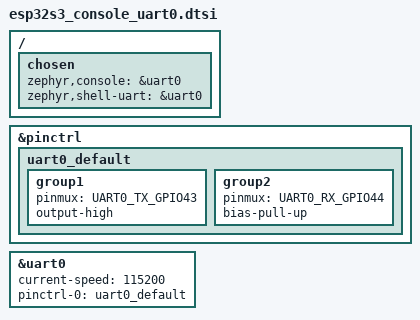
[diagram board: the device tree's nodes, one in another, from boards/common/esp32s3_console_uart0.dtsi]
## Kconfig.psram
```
# SPDX-License-Identifier: MIT
#
# DT-driven PSRAM auto-enable for ESP32 boards.
#
# Upstream Zephyr's esp32*_wroom_n*r*.dtsi files override psram0 size when
# the chip variant has PSRAM stuffed (R-suffix in the Espressif part number).
# We auto-enable PSRAM whenever the DTS size is non-zero — the upstream
# Kconfig.spiram then auto-reads ESP_SPIRAM_SIZE from the same DT property.
#
# Boards without PSRAM include a non-R-suffix dtsi (e.g. esp32s3_wroom_n8),
# which leaves psram0 at size = 0 — auto-detect leaves PSRAM off for them.
# ESP32-C3 and ESP32-C6 are outside Kconfig.spiram's SOC gate entirely, so
# this symbol doesn't exist on those builds — no effect.
#
# Mode (QUAD vs OCT) cannot be auto-picked here: upstream Kconfig.spiram
# sets an unconditional `default SPIRAM_MODE_QUAD` on the choice, which wins
# over any conditional default we'd add. ESP32-S3 R8 boards (8 MB OPI octal
# PSRAM) must set CONFIG_SPIRAM_MODE_OCT=y in their board.conf. R2 boards
# (2 MB QSPI quad) need nothing — QUAD is the upstream default.

config ESP_SPIRAM
	default y if (SOC_SERIES_ESP32 || SOC_SERIES_ESP32S2 || SOC_SERIES_ESP32S3 || SOC_SERIES_ESP32C5) && \
		"$(dt_node_int_prop_int,$(dt_nodelabel_path,psram0),size)" != 0
```

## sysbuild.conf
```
# ZephCore Sysbuild Configuration
# Enables the MCUboot bootloader whenever --sysbuild is passed. Used by the
# ESP32-S3/C-series release builds (companion and repeater: MCUboot @ 0x0, app
# @ 0x10000) and by any build with wifi_ota.conf. Classic ESP32, nRF52, nRF54L,
# MG24 and STM32WL builds do not use --sysbuild.

SB_CONFIG_BOOTLOADER_MCUBOOT=y
SB_CONFIG_MCUBOOT_MODE_OVERWRITE_ONLY=y

# Explicit since Zephyr 4.5: 51ef282b5f1 moved Espressif sysbuild to the generic
# MCUboot defaults, whose signature type is RSA.  That silently turned the
# bootloader into an RSA-2048 verifier keyed to MCUboot's public development
# key -- no real security, ~19 KB of mbedTLS/PSA that overflowed the 64 KB
# MCUboot slot on several boards (the app written at 0x10000 then overwrites
# the bootloader's tail), and a bootloader that rejects the hash-only images
# every deployed ESP32 node and WiFi-OTA update uses.  NONE = hash check only,
# exactly what v4.4 built.  Moving to real signing (own key) is a separate
# decision with OTA consequences.
SB_CONFIG_BOOT_SIGNATURE_TYPE_NONE=y
```

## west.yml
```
manifest:
  remotes:
    - name: zephyrproject-rtos
      url-base: https://github.com/zephyrproject-rtos

  projects:
    - name: zephyr
      remote: zephyrproject-rtos
      revision: 54b1e23b9ce303480ccbcab4b80d6f2f8442dac1
      import: true

  self:
    path: zephcore
```

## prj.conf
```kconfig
# ZephCore - Main Project Configuration
#
# This file contains ONLY console/logging setup and includes common configs.
# Platform-specific configs are in boards/common/<platform>_common.conf
# Board-specific configs (pins only) are in boards/<board>.conf
#
# Include hierarchy:
#   prj.conf (this file - logging/console)
#   → boards/common/zephcore_common.conf (app features, crypto, sensors)
#   → boards/common/<platform>_common.conf (BLE, flash, storage)
#   → boards/<board>.conf (pins, board-specific features)

# ========== Console & Logging ==========
CONFIG_CONSOLE=y
CONFIG_UART_CONSOLE=y
CONFIG_UART_INTERRUPT_DRIVEN=y
CONFIG_RING_BUFFER=y

# Production by default — add boards/common/debug.conf to enable logging.
CONFIG_LOG=n
CONFIG_ASSERT=n
CONFIG_USE_SEGGER_RTT=n
CONFIG_THREAD_NAME=n

# Reboot on any fatal error (stack overflow, hard fault, etc.) instead of
# spinning forever. Asserts are disabled so they won't reach here, but all
# other fatal paths (k_panic, CPU exceptions) still get a clean reboot.
CONFIG_ZEPHCORE_RESET_ON_FATAL_ERROR=y

# ========== Power Management ==========
# Device PM only — CONFIG_PM (system PM) stays off. nRF52/nRF54L have no
# devicetree power-states in Zephyr 4.4 (WFI in the idle thread is already
# the low-power System ON state); ESP32/STM32WL do have states but need
# their own bring-up (BLE/WiFi/radio wake paths) before CONFIG_PM can go on.
#
# CONFIG_PM_DEVICE alone suspends nothing automatically: PM actions run only
# when we call pm_device_action_run() (always from the main thread). The
# system-managed auto-suspend (PM_DEVICE_SYSTEM_MANAGED) is compiled only
# under CONFIG_PM; it is pinned off here so a platform that later enables
# CONFIG_PM can't silently start suspending devices from the idle thread.
#
# Why device PM is on:
# - gnss-nmea-generic inits pm_device_init_suspended() under CONFIG_PM_DEVICE
#   and never opens its modem pipe until resumed; ZephyrGPSManager resumes it
#   once at boot (this was the old "PM broke GPS" trap).
# - GPS standby suspends the GNSS UARTE — an armed UARTE RX holds HFCLK
#   (~0.5-1 mA continuous on nRF52840) even with the GPS module powered off.
#   See adapters/gps/ZephyrGPSManager.cpp for the full strategy.
CONFIG_PM_DEVICE=y
CONFIG_PM_DEVICE_SYSTEM_MANAGED=n
```

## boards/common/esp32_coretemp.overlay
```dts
/*
 * SPDX-License-Identifier: MIT
 * ESP32-S3 / C3 / C6: enable the SoC's internal temperature sensor.
 *
 * Every Espressif SoC dtsi that has the sensor declares it as `coretemp`,
 * disabled, behind the alias `die-temp0`. Enabling the node is all it takes:
 * CONFIG_ESP32_TEMP defaults on with it, and ZephyrBoard::getMCUTemperature()
 * finds it through the alias.
 *
 * Not for the classic ESP32, which has no such node (a reference to &coretemp
 * is a dtc error there) and no driver. CMakeLists.txt skips it for that SoC.
 */

&coretemp {
	status = "okay";
};
```

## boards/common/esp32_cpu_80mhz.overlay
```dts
/*
 * SPDX-License-Identifier: MIT
 * ESP32 family: run the CPU at 80 MHz.
 *
 * Espressif parts have no equivalent of the nRF52's "idle at microamps in
 * WFI": WAITI gates the core clock but leaves the PLL, peripherals and RAM
 * powered, so an idle ESP32 sits in the tens of mA and CPU frequency is a
 * first-order term in that. Arduino MeshCore ships its ESP32 variants at
 * 80 MHz for the same reason (ESP32_CPU_FREQ=80 in variants/heltec_v3,
 * heltec_v4, heltec_tracker, rak3112, xiao_c3, ...).
 *
 * hal_espressif computes CONFIG_ESP_DEFAULT_CPU_FREQ_MHZ as this property / 1e6
 * straight from /cpus/cpu@0, so 80 needs no module patch.  (Older pins used a
 * fixed 96/120/160/240 map that omitted 80; we carried hal-espressif 0002 for
 * it until the Zephyr-main bump.)  Do NOT use 96 -- it is an ESP32-H2
 * frequency, rejected by rtc_clk_cpu_freq_mhz_to_config() on every SoC we
 * build, and it fails at BOOT rather than at build time.
 *
 * The mesh workload is event-driven and nowhere near CPU-bound: wake on a
 * packet, run some AES and LittleFS, go back to idle. Airtime dominates every
 * latency that matters — the slowest presets spend seconds on air per packet.
 *
 * Only cpu0 is set, deliberately. clock_control_esp32.c reads exactly
 * DT_INST(0, DT_CPU_COMPAT) — cpu0 — so a cpu1 property is never consulted,
 * and omitting it lets this one file serve the dual-core Xtensa parts (S3,
 * classic) and the single-core RISC-V parts (C3, C6) alike. Referencing
 * &cpu1 here would be a dtc error on the latter.
 *
 * Applied automatically to every ESP32 build — see the ESP32 CPU clock block
 * in CMakeLists.txt. Kept out of the per-board DTS files on purpose: one place
 * to change. Without it a build runs at its SoC's maximum (240 MHz on
 * S3/classic, 160 MHz on C3/C6).
 */

&cpu0 {
	clock-frequency = <DT_FREQ_M(80)>;
};
```

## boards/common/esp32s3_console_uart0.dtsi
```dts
/*
 * Reroute console + shell off USB Serial/JTAG onto uart0 (physical TX/RX).
 *
 * ESP32-S3 USB Serial/JTAG shares the D+/D- pins with USB OTG and only one
 * controller can own the port at a time.  When esp32s3_usb.conf disables USB
 * Serial/JTAG and hands the port to USB OTG, a console chosen as usb_serial
 * would go silent — this gives it a home on uart0 instead.
 *
 * Boards that default their console to USB Serial/JTAG must NOT include this
 * from board.overlay: that applies to every build of the board, including the
 * ones that never enable USB OTG, and silently strands the console (and the
 * observer/repeater serial CLI, which falls back to the chosen console) on
 * GPIO43/44.  It is included from the auto-paired esp32s3_usb.overlay instead,
 * so it follows esp32s3_usb.conf.
 *
 * Boards whose console really is a physical uart0 — Heltec V3/V4/V43, and
 * ThinkNode M9 (USB-C via a CH9102-class bridge into UART0, native USB pads not
 * bonded) — do include it unconditionally, which is correct for them.
 *
 * uart0 is disabled by default in the ESP32-S3 SoC dtsi, so we enable it and
 * pin it to the chip's ROM-default UART0 pads (GPIO43 TX / GPIO44 RX) — the
 * same pins Heltec uses.  Without this the console would point at a disabled,
 * un-pinned node and produce no output at all.
 */
#include <zephyr/dt-bindings/pinctrl/esp-pinctrl-common.h>
#include <zephyr/dt-bindings/pinctrl/esp32s3-pinctrl.h>
#include <zephyr/dt-bindings/pinctrl/esp32s3-gpio-sigmap.h>

&pinctrl {
	uart0_default: uart0_default {
		group1 {
			pinmux = <UART0_TX_GPIO43>;
			output-high;
		};
		group2 {
			pinmux = <UART0_RX_GPIO44>;
			bias-pull-up;
		};
	};
};

&uart0 {
	status = "okay";
	current-speed = <115200>;
	pinctrl-0 = <&uart0_default>;
	pinctrl-names = "default";
};

/ {
	chosen {
		zephyr,console    = &uart0;
		zephyr,shell-uart = &uart0;
	};
};
```

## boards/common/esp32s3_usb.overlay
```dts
/*
 * Device-tree half of esp32s3_usb.conf — auto-paired by the
 * zephcore_auto_pair_overlay() helper in CMakeLists.txt, so it is applied if
 * and only if the build actually passes boards/common/esp32s3_usb.conf.
 *
 * esp32s3_usb.conf disables USB Serial/JTAG and hands the shared D+/D- pins to
 * the USB OTG controller (the CDC-ACM companion channel).  Any board whose
 * console rides usb_serial would go silent at that moment, so the console is
 * rerouted to uart0 here — in the paired overlay rather than in board.overlay,
 * because board.overlay applies to EVERY build of the board regardless of role.
 *
 * That is the bug this file exists to prevent: xiao_esp32s3 and station_g2 used
 * to include the reroute unconditionally, which silently moved the console (and
 * with it the observer/repeater serial CLI, which falls back to the chosen
 * console) onto GPIO43/44 in builds that never enabled USB OTG at all.
 *
 * Devicetree is processed before Kconfig, so an overlay cannot test
 * CONFIG_ZEPHCORE_COMPANION_USB — the conf/overlay pairing is what makes this
 * conditional.
 *
 * Boards whose console is already a physical uart0 (Heltec V3/V4/V43, ThinkNode
 * M9) are unaffected: the include re-asserts the same uart0 + GPIO43/44 setup
 * they already have.
 */
#include "esp32s3_console_uart0.dtsi"
```

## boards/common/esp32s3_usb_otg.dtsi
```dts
/*
 * ESP32-S3 USB OTG (DWC2) — companion USB transport.
 *
 * Enables the snps,dwc2 USB OTG controller and attaches a CDC-ACM UART node
 * for the binary companion protocol.  The DWC2 driver is only compiled when
 * CONFIG_USB_DEVICE_STACK_NEXT=y (set by boards/common/esp32s3_usb.conf);
 * without that conf this node is inert.
 *
 * Boards whose default console rides USB Serial/JTAG (shares D+/D- with USB
 * OTG) must also reroute the console off the shared pins — see
 * esp32s3_console_uart0.dtsi.
 */
zephyr_udc0: &usb_otg {
	status = "okay";
};

&zephyr_udc0 {
	cdc_acm_uart: cdc_acm_uart {
		compatible = "zephyr,cdc-acm-uart";
	};
};
```

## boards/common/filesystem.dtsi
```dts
/*
 * Common LittleFS filesystem configuration for ZephCore boards.
 * Include this in board overlays to get standard /lfs mount.
 *
 * Requires board to define: &lfs_partition
 *
 * SPDX-License-Identifier: MIT
 */

/ {
	fstab {
		compatible = "zephyr,fstab";

		/* Internal LittleFS for identity, prefs */
		lfs: lfs {
			compatible = "zephyr,fstab,littlefs";
			mount-point = "/lfs";
			partition = <&lfs_partition>;
			automount;
			read-size = <16>;
			prog-size = <16>;
			cache-size = <64>;
			lookahead-size = <32>;
			block-cycles = <512>;
		};
	};
};
```

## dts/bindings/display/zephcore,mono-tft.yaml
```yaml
# Copyright (c) 2026 ZephCore
#
# SPDX-License-Identifier: MIT

description: |
  Monochrome wrapper for RGB TFT displays (ST7789V, etc.)

  Reports PIXEL_FORMAT_MONO01 to CFB, so the framebuffer is ~4 KB
  (1 bit per pixel) instead of the ~64 KB RGB565 buffer that CFB
  would otherwise allocate. On flush, converts row-major 1bpp to
  RGB565 and pushes to the underlying display row by row.

compatible: "zephcore,mono-tft"

properties:
  tft-dev:
    type: phandle
    required: true
    description: The underlying RGB TFT display device (e.g. ST7789V. etc.).

  width:
    type: int
    required: true
    description: Display width in pixels.

  height:
    type: int
    required: true
    description: Display height in pixels.
```

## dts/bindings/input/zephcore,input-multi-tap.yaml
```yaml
# Copyright 2025 ZephCore
# SPDX-License-Identifier: MIT

description: |
  Input multi-tap pseudo-device.

  Listens for key-press events from a parent input device and counts rapid
  taps within a configurable window. When the window expires, emits a key
  code based on the number of taps observed.

  The tap-codes array maps tap counts to output key codes:
    tap-codes[0] = code emitted for 1 tap
    tap-codes[1] = code emitted for 2 taps
    ...up to 5 entries.

  If the tap count reaches the length of tap-codes, the code is emitted
  immediately (no need to wait for more taps). Otherwise the tap-delay-ms
  window must expire before the code is emitted.

  Example (single button with page-next and buzzer-toggle):
    user_btn_multitap {
        compatible = "zephcore,input-multi-tap";
        input = <&buttons>;
        input-codes = <INPUT_KEY_A>;
        tap-codes = <INPUT_KEY_1 INPUT_KEY_B>;
        tap-delay-ms = <400>;
    };

compatible: "zephcore,input-multi-tap"

properties:
  input:
    type: phandle
    description: |
      Input device phandle to listen to. If not specified, listens for
      input from all devices.

  input-codes:
    type: array
    required: true
    description: |
      Array of input event key codes to watch (INPUT_KEY_* or INPUT_BTN_*).

  tap-codes:
    type: array
    required: true
    description: |
      Array of output key codes for each tap count (1-based).
      Entry 0 = 1 tap, entry 1 = 2 taps, etc.
      Maximum 5 entries.

  tap-delay-ms:
    type: int
    required: true
    description: |
      Maximum time in milliseconds between taps. After the last tap,
      this delay must expire before the tap code is emitted.
```

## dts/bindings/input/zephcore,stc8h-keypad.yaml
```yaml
# Copyright 2026 ZephCore
# SPDX-License-Identifier: MIT

description: |
  STC8H companion-MCU keypad (I2C).

  A small helper MCU scans the key matrix and presents one register interface
  over I2C. Used by the Elecrow ThinkNode M9, whose keypad is its only input
  device — there is no user button on that board.

  Protocol (as recovered from the stock keypad firmware — note the key
  register is 0x01, not the 0x05 "matrix key" register that the reference
  header documents; that define is dead code and 0x05 reads as 0xFF):
    reg 0x01        code of the last key pressed (latched; 0x88 = invalid)
    reg 0x01..0x04  battery millivolts, little-endian (same base register)
    reg 0x06        state; writing 0x01 requests sleep

  The MCU raises its interrupt line (idle-low, rising edge) when a key is
  pressed. The driver reads register 0x01 on that edge and reports the result
  through Zephyr's input subsystem. If no interrupt GPIO is supplied the
  driver falls back to polling.

  Example:
    &i2c1 {
        keypad: keypad@6c {
            compatible = "zephcore,stc8h-keypad";
            reg = <0x6c>;
            irq-gpios = <&gpio0 12 GPIO_ACTIVE_HIGH>;
            poll-interval-ms = <40>;
        };
    };

compatible: "zephcore,stc8h-keypad"

include: [i2c-device.yaml]

properties:
  irq-gpios:
    type: phandle-array
    description: |
      Key-press interrupt from the helper MCU. Idle-low, rising edge on press.
      Optional — the driver polls when it is absent.

  poll-interval-ms:
    type: int
    default: 40
    description: |
      Poll period. Used as the sole scan mechanism when irq-gpios is absent,
      and as a safety net for a missed edge when it is present.
```

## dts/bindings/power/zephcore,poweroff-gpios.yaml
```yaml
# Copyright 2026 ZephCore
# SPDX-License-Identifier: MIT

description: |
  Board power-latch and switched-rail release list.

  Lists GPIOs that must be driven to their INACTIVE level as the very last
  step before sys_poweroff(), after every other peripheral has been shut down
  and after the sw0 wake button has been released.

  This exists for boards whose supply rail is latched on by the MCU rather
  than by a mechanical switch — typically a soft-power design where a
  companion I/O controller holds the regulator enabled only while the MCU
  keeps a "hold" line asserted. On such boards sys_poweroff() alone is not a
  real power-off: the SoC enters System OFF at ~1 uA, but nRF GPIO output
  latches persist across the transition, so the hold line stays asserted and
  the rail (plus whatever else it feeds) keeps draining the battery.

  The same applies to a switched rail that is enabled by a GPIO at boot (a
  gpio-hog or a regulator-fixed enable): the latch keeps it on through
  System OFF unless it is listed here (RAK4631 / RAK3401 1W: WB_IO2, the
  WisBlock 3V3_S rail).

  Order matters and is preserved: list downstream loads first and the rail
  latch itself last, so the board is quiesced before the supply is cut.

  Boards that do not define a node with this compatible are completely
  unaffected — the release loop compiles to nothing.

  Note that these are usually the same pins a board asserts at boot via
  gpio-hog. The hog performs the early boot assert (PRE_KERNEL, before any
  driver runs); this node performs the shutdown release. Referencing a
  hogged pin here is intentional and safe — a gpio-hog is an init-time
  configuration, not a runtime reservation.

  Example (muzi works R1 Neo — I/O controller gated DCDC rail):
    poweroff_gpios: poweroff-gpios {
        compatible = "zephcore,poweroff-gpios";
        gpios = <&gpio1 5  GPIO_ACTIVE_HIGH>,   /* SX1262 module power */
                <&gpio0 29 GPIO_ACTIVE_HIGH>,   /* I/O controller "MCU on" */
                <&gpio0 13 GPIO_ACTIVE_HIGH>;   /* DCDC latch - cuts the rail */
    };

compatible: "zephcore,poweroff-gpios"

properties:
  gpios:
    type: phandle-array
    required: true
    description: |
      GPIOs to drive INACTIVE (per each entry's own GPIO_ACTIVE_* flag)
      immediately before sys_poweroff(). Listed in shutdown order:
      downstream loads first, supply latch last.
```

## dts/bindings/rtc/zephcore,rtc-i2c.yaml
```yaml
# SPDX-License-Identifier: MIT
#
# Data-only descriptor for an I2C RTC chip read by ZephyrRTCDiscover
# (adapters/clock/ZephyrRTCDiscover.c). This binds NO Zephyr RTC driver —
# the chip is accessed with raw I2C using the register layout described by
# the properties below. This keeps the boot-time RTC restore compact
# (~2-3 KB total, "Path B") instead of pulling in the full RTC subsystem.
#
# All supported chips use a 7-byte time block (sec, min, hour, then
# weekday/date, month, year) starting at "time-reg", BCD in every field but
# the weekday. The day-of-month byte offset varies between parts, captured
# by "date-index". The weekday is written as a number 0-6 (Sunday 0), as
# Zephyr's DS3231, PCF8563 and RV3028 drivers write it, or as one bit per
# day where "weekday-one-hot" is set.

description: ZephCore data-only I2C RTC descriptor (raw-I2C, no Zephyr RTC driver)

compatible: "zephcore,rtc-i2c"

include: [i2c-device.yaml]

properties:
  time-reg:
    type: int
    required: true
    description: Register address of the seconds byte (start of the 7-byte time block).

  date-index:
    type: int
    required: true
    description: >
      Byte offset of the day-of-month within the 7-byte block. 4 for chips
      ordered sec/min/hour/weekday/date/month/year (DS3231, RV3028, RX8130CE);
      3 for PCF8563 which swaps to sec/min/hour/date/weekday/month/year.

  status-reg:
    type: int
    required: true
    description: >
      Register holding the "time invalid / power was lost" flag. Use 0xFF to
      indicate the flag lives in the seconds byte itself (PCF8563 VL bit).

  status-mask:
    type: int
    required: true
    description: Bit mask within status-reg that means the held time is unreliable.

  zero-mask:
    type: uint8-array
    description: >
      Seven bytes, one per register of the time block in block order: the
      bits the chip's data sheet shows as reading 0. A device that
      shows one of them, or seconds, minutes, date or month out of range
      while the power-loss flag does not read as set, on two reads, is not
      this RTC and is never adopted. Leave it out for a chip whose unused
      bits are not documented as reading 0.

  weekday-one-hot:
    type: boolean
    description: >
      The weekday register holds one bit per day (Sunday bit 0 to Saturday
      bit 6) rather than a number 0-6. Set it for a chip whose data sheet
      says so, such as the RX8130CE.

  twelve-hour-bit:
    type: uint8-array
    description: >
      [register mask]: a bit outside the time block that reads set in
      12-hour mode, where clearing it makes the chip convert its own
      hours to 24-hour, such as the RV3028's Control 2 12_24. Once the
      chip is cleanly identified, a set bit is cleared before a time is
      taken from it. No time is taken if the register cannot be read or
      reads FFh, or if the write or the re-read fails.

  rv3028-eeprom-config:
    type: uint8-array
    description: >
      RV3028 only. (register, mask, value) triplets for the chip's
      EEPROM-backed configuration registers 0x35 (CLKOUT) to 0x37
      (backup switchover and trickle charger), one triplet per register,
      masking implemented bits only (35h bits 5:4 are not); any other
      triplet is ignored. When a read identifies the chip, it is
      adopted, and no switchover showed during its time read, any
      register whose masked bits differ is written to the chip's EEPROM,
      one byte at a time with backup switchover held off, so the chip's
      own refresh from EEPROM keeps it. If that fails, the config is set
      in the RAM mirror once the chip's EEbusy flag reads 0, and lasts
      until the chip's next refresh from EEPROM (daily while EERD is
      clear); if EEbusy never clears, switchover stays as the store left
      it, off once the store has disabled it, until a retry or that
      refresh. The store is retried up to 3 times, 10 minutes apart,
      identifying the chip again first; a boot whose read could not
      identify it cleanly, or whose 12-hour clear failed, waits for those
      retries. The time is read at
      boot and written on each sync within 2000-2099 with the chip's
      backup switch flag cleared before and checked after. A write sets
      year 00h first and the real year last, so a write cut by a power
      loss reads as "time not yet set", and a write not confirmed is
      repeated every 5 s, up to 12 times. Set it only on a board whose
      backup supply is known: trickle charging suits a supercapacitor or
      rechargeable cell, never a primary cell.
```

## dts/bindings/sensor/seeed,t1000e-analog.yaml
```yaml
# Copyright (c) 2026 ZephCore
# SPDX-License-Identifier: MIT

description: |
  Seeed Tracker T1000-E onboard analog sensors.

  Two passive parts sit on the board's switched 3V3 sensor rail and are read
  through the SoC's ADC:

    - An NTC thermistor forming the upper leg of a divider, reported as
      SENSOR_CHAN_AMBIENT_TEMP in degrees C. The resistance is converted
      through the same resistance/temperature table Seeed's own firmware uses,
      so readings match the stock and Arduino MeshCore builds.

    - A photocell, reported as SENSOR_CHAN_LIGHT. Seeed's firmware maps it to
      a 0-100 scale rather than to lux, and Arduino MeshCore forwards that
      scale verbatim as CayenneLPP luminosity, so this driver does the same.
      The value is a percentage despite the channel's nominal lux units.

  Neither divider outputs a valid voltage until the rail regulator is on and
  given time to settle, so the driver switches it around each sample fetch
  rather than leaving it on.

compatible: "seeed,t1000e-analog"

include: [sensor-device.yaml]

properties:
  io-channels:
    required: true
    description: |
      ADC channels, in the order named by io-channel-names: "ntc", "light" and
      "vcc". "vcc" is the battery/rail divider channel — converting the NTC
      divider needs the rail voltage feeding it, not a constant.

  io-channel-names:
    required: true

  vcc-mv-multiplier:
    type: int
    required: true
    description: |
      Scales the raw "vcc" reading to millivolts as mv = raw * multiplier / 4096.
      Same convention as the zephyr,user vbat-mv-multiplier property, and
      normally the same value, since it is normally the same channel.

  vcc-max-mv:
    type: int
    default: 3300
    description: |
      Rail voltage ceiling in millivolts, used to clamp the measured "vcc"
      before it becomes the NTC divider reference. Above the regulator's
      dropout the divider is fed from the fixed rail rather than from the
      cell, so the higher battery reading would overstate it. Only a cell
      flat enough to drag the rail down reads below this.

  power-gpios:
    type: phandle-array
    description: |
      Optional sensor-enable pin, asserted for the duration of a sample fetch,
      in addition to power-supply. The T1000-E has none (P0.4 is a voltage
      detect input, not SENSOR_EN) and leaves this unset.

  power-supply:
    type: phandle
    description: |
      Regulator for the switched sensor rail (PIN_3V3_EN, P1.6 on the
      T1000-E), enabled for the duration of a sample fetch. Refcounted, so it
      nests safely with the battery read, which switches the same rail.

  settle-time-ms:
    type: int
    default: 10
    description: |
      Delay between asserting the rail and enable pin and sampling, to let the
      divider and its decoupling capacitor settle.

  ntc-series-ohms:
    type: int
    default: 8250
    description: |
      Series resistor in the lower leg of the NTC divider, in ohms.
```

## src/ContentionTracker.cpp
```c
/*
 * SPDX-License-Identifier: MIT
 * Contention estimate — dupe-counting EMA
 */

#include <mesh/ContentionTracker.h>
#include <mesh/Packet.h>
#include <string.h>

namespace mesh {

ContentionTracker::ContentionTracker()
	: _next_idx(0), _ema_x256(0), _finalized_count(0),
	  _last_retransmit_ms(0), _last_decay_ms(0)
{
	memset(_ring, 0, sizeof(_ring));
}

/* FNV-1a over payload_type + first 8 payload bytes */
uint32_t ContentionTracker::computePacketHash32(const Packet *pkt)
{
	uint32_t h = 0x811c9dc5u; /* FNV-1a offset basis */
	uint8_t t = pkt->getPayloadType();
	h = (h ^ t) * 0x01000193u;
	int n = pkt->payload_len < 8 ? pkt->payload_len : 8;
	for (int i = 0; i < n; i++) {
		h = (h ^ pkt->payload[i]) * 0x01000193u;
	}
	return h;
}

int ContentionTracker::findEntry(uint32_t hash32) const
{
	for (int i = 0; i < RING_SIZE; i++) {
		if (_ring[i].active && _ring[i].hash32 == hash32) {
			return i;
		}
	}
	return -1;
}

void ContentionTracker::finalizeEntry(int idx)
{
	if (!_ring[idx].active) return;

	uint32_t sample_x256 = (uint32_t)_ring[idx].dupe_count << 8;

	int32_t diff = (int32_t)sample_x256 - (int32_t)_ema_x256;

	if (_finalized_count < WARMUP_PACKETS) {
		/* Warmup: seed EMA with fast convergence */
		if (_finalized_count == 0) {
			_ema_x256 = sample_x256;
		} else {
			_ema_x256 = (uint32_t)((int32_t)_ema_x256 + (diff >> 1));
		}
	} else {
		_ema_x256 = (uint32_t)((int32_t)_ema_x256 + (diff >> EMA_SHIFT));
	}

	_finalized_count++;
	_ring[idx].active = false;
}

void ContentionTracker::trackRetransmit(uint32_t hash32, uint32_t now_ms)
{
	_last_retransmit_ms = now_ms;

	/* Evict oldest if ring slot occupied */
	if (_ring[_next_idx].active) {
		finalizeEntry(_next_idx);
	}

	Entry &e = _ring[_next_idx];
	e.hash32 = hash32;
	e.first_seen_ms = now_ms;
	e.dupe_count = 0;
	e.active = true;

	_next_idx = (_next_idx + 1) % RING_SIZE;
}

bool ContentionTracker::recordDupeIfTracked(uint32_t hash32, uint32_t now_ms)
{
	int idx = findEntry(hash32);
	if (idx < 0) return false;

	Entry &e = _ring[idx];

	if (now_ms - e.first_seen_ms > WINDOW_MS) {
		finalizeEntry(idx);
		return false;
	}

	if (e.dupe_count < 255) {
		e.dupe_count++;
	}
	return true;
}

int ContentionTracker::extractDupeCount(uint32_t hash32)
{
	int idx = findEntry(hash32);
	if (idx < 0) return -1;
	int count = (int)_ring[idx].dupe_count;
	finalizeEntry(idx);  /* folds into EMA, marks inactive */
	return count;
}

void ContentionTracker::tick(uint32_t now_ms)
{
	for (int i = 0; i < RING_SIZE; i++) {
		if (_ring[i].active && now_ms - _ring[i].first_seen_ms > WINDOW_MS) {
			finalizeEntry(i);
		}
	}

	/* Decay EMA toward 0 if no retransmit in STALE_MS.  Paced by wall clock
	 * (one 1/8 step per DECAY_PERIOD_MS) rather than one step per call, so
	 * the decay rate no longer depends on how often the event loop happens
	 * to call us — see DECAY_PERIOD_MS. */
	if (_last_retransmit_ms != 0 && now_ms - _last_retransmit_ms > STALE_MS &&
	    _ema_x256 > 0) {
		if (_last_decay_ms == 0) {
			/* Arm one full period in the past, so the loop below applies a step on
			 * this call. Unsigned wraparound keeps it exact near zero. */
			_last_decay_ms = now_ms - DECAY_PERIOD_MS;
		}
		for (int n = 0; n < MAX_DECAY_CATCHUP; n++) {
			if (now_ms - _last_decay_ms < DECAY_PERIOD_MS ||
			    _ema_x256 == 0) {
				break;
			}
			/* At least 1, or the value sticks below 8 and never rests. */
			uint32_t step = _ema_x256 >> EMA_SHIFT;

			_ema_x256 -= step ? step : 1;
			_last_decay_ms += DECAY_PERIOD_MS;
		}
	} else {
		/* Not decaying — restart the phase next time we are. */
		_last_decay_ms = 0;
	}
}

uint32_t ContentionTracker::msUntilNextTick(uint32_t now_ms) const
{
	uint32_t next = MAINTENANCE_IDLE;

	/* Soonest ring entry to fall out of the observation window. */
	for (int i = 0; i < RING_SIZE; i++) {
		if (!_ring[i].active) {
			continue;
		}
		next = maintenanceSooner(
			next, maintenanceUntil(now_ms,
					       _ring[i].first_seen_ms + WINDOW_MS + 1));
	}

	/* Stale-decay step, only while there is EMA left to decay. */
	if (_last_retransmit_ms != 0 && _ema_x256 > 0) {
		uint32_t stale_at = _last_retransmit_ms + STALE_MS + 1;

		if (now_ms - _last_retransmit_ms > STALE_MS) {
			/* Already stale: next step is one period after the last
			 * one (or immediately, if we have not started yet). */
			next = maintenanceSooner(
				next, _last_decay_ms == 0
					      ? 0
					      : maintenanceUntil(now_ms,
								 _last_decay_ms +
									 DECAY_PERIOD_MS));
		} else {
			next = maintenanceSooner(next,
						 maintenanceUntil(now_ms, stale_at));
		}
	}

	return next;
}

float ContentionTracker::getContentionEstimate() const
{
	return (float)_ema_x256 / 256.0f;
}

} /* namespace mesh */
```

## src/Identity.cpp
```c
/*
 * SPDX-License-Identifier: MIT
 * ZephCore Identity - Ed25519 sign/verify (Monocypher backend)
 *
 * Backed by Monocypher (lib/monocypher). The persisted private key keeps the
 * historical 64-byte *expanded* layout — prv[0..31] = clamped SHA-512(seed)
 * scalar `a`, prv[32..63] = nonce prefix — so identities written by older
 * (orlp/ed25519) firmware load, sign, and key-exchange byte-for-byte unchanged.
 * Signing is built from Monocypher's low-level EdDSA primitives because the
 * stored expanded key carries no seed to feed the high-level API.
 */

#include <mesh/Identity.h>
#include <string.h>
#include <monocypher.h>
#include <monocypher-ed25519.h>

namespace mesh {

/* Expand a 32-byte seed into the stored 64-byte private key (orlp-compatible
 * layout): clamped SHA-512(seed)[0..31] || SHA-512(seed)[32..63]. */
static void expandSeed(uint8_t prv[PRV_KEY_SIZE], const uint8_t seed[SEED_SIZE])
{
	crypto_sha512(prv, seed, SEED_SIZE);
	prv[0]  &= 248;
	prv[31] &= 63;
	prv[31] |= 64;
}

/* Sign from the expanded key (no seed). RFC 8032 Ed25519 assembled from
 * Monocypher scalar/point primitives — byte-identical to the prior orlp
 * implementation (verified by known-answer tests). */
static void signExpanded(uint8_t sig[SIGNATURE_SIZE],
			 const uint8_t prv[PRV_KEY_SIZE],
			 const uint8_t pub[PUB_KEY_SIZE],
			 const uint8_t *msg, size_t msg_len)
{
	uint8_t r64[64], hram64[64], r[32], hram[32];
	crypto_sha512_ctx h;

	/* r = SHA-512(prefix || msg) mod L ; prefix = prv[32..63] */
	crypto_sha512_init(&h);
	crypto_sha512_update(&h, prv + 32, 32);
	crypto_sha512_update(&h, msg, msg_len);
	crypto_sha512_final(&h, r64);
	crypto_eddsa_reduce(r, r64);

	/* R = r·B -> sig[0..31] */
	crypto_eddsa_scalarbase(sig, r);

	/* hram = SHA-512(R || A || msg) mod L */
	crypto_sha512_init(&h);
	crypto_sha512_update(&h, sig, 32);
	crypto_sha512_update(&h, pub, 32);
	crypto_sha512_update(&h, msg, msg_len);
	crypto_sha512_final(&h, hram64);
	crypto_eddsa_reduce(hram, hram64);

	/* S = (hram·a + r) mod L ; a = prv[0..31] -> sig[32..63] */
	crypto_eddsa_mul_add(sig + 32, hram, prv, r);

	/* r / r64 are nonce material — leaking them leaks the private key. */
	crypto_wipe(r64, sizeof(r64));
	crypto_wipe(r, sizeof(r));
}

/* X25519 over Ed25519 keys: convert the peer's Edwards public key to its
 * Montgomery form, then scalar-multiply by our scalar (prv[0..31]). Raw
 * shared secret, no output hashing — matches the prior orlp key_exchange. */
static void calcECDH(uint8_t secret[CIPHER_KEY_SIZE * 2],
		     const uint8_t prv[PRV_KEY_SIZE],
		     const uint8_t other_pub[PUB_KEY_SIZE])
{
	uint8_t other_x[32];
	crypto_eddsa_to_x25519(other_x, other_pub);
	crypto_x25519(secret, prv, other_x);
}

Identity::Identity()
{
	memset(pub_key, 0, sizeof(pub_key));
}

Identity::Identity(const char *pub_hex)
{
	Utils::fromHex(pub_key, PUB_KEY_SIZE, pub_hex);
}

bool Identity::verify(const uint8_t *sig, const uint8_t *message, int msg_len) const
{
	return crypto_ed25519_check(sig, pub_key, message, (size_t)msg_len) == 0;
}

bool Identity::readFrom(const uint8_t *src, size_t len)
{
	if (len < PUB_KEY_SIZE) return false;
	memcpy(pub_key, src, PUB_KEY_SIZE);
	return true;
}

bool Identity::writeTo(uint8_t *dest, size_t max_len) const
{
	if (max_len < PUB_KEY_SIZE) return false;
	memcpy(dest, pub_key, PUB_KEY_SIZE);
	return true;
}

LocalIdentity::LocalIdentity()
{
	memset(prv_key, 0, sizeof(prv_key));
}

LocalIdentity::LocalIdentity(const char *prv_hex, const char *pub_hex) : Identity(pub_hex)
{
	Utils::fromHex(prv_key, PRV_KEY_SIZE, prv_hex);
}

LocalIdentity::LocalIdentity(RNG *rng)
{
	uint8_t seed[SEED_SIZE];
	rng->random(seed, SEED_SIZE);
	fromSeed(seed);
	Utils::secureZeroize(seed, sizeof(seed));
}

void LocalIdentity::fromSeed(const uint8_t seed[SEED_SIZE])
{
	expandSeed(prv_key, seed);
	crypto_eddsa_scalarbase(pub_key, prv_key);  /* pub = a·B */
}

bool LocalIdentity::validatePrivateKey(const uint8_t prv[64])
{
	uint8_t pub[32];
	crypto_eddsa_scalarbase(pub, prv);
	if (pub[0] == 0x00 || pub[0] == 0xFF) return false;

	const uint8_t test_client_prv[64] = {
		0x70, 0x65, 0xe1, 0x8f, 0xd9, 0xfa, 0xbb, 0x70,
		0xc1, 0xed, 0x90, 0xdc, 0xa1, 0x99, 0x07, 0xde,
		0x69, 0x8c, 0x88, 0xb7, 0x09, 0xea, 0x14, 0x6e,
		0xaf, 0xd9, 0x3d, 0x9b, 0x83, 0x0c, 0x7b, 0x60,
		0xc4, 0x68, 0x11, 0x93, 0xc7, 0x9b, 0xbc, 0x39,
		0x94, 0x5b, 0xa8, 0x06, 0x41, 0x04, 0xbb, 0x61,
		0x8f, 0x8f, 0xd7, 0xa8, 0x4a, 0x0a, 0xf6, 0xf5,
		0x70, 0x33, 0xd6, 0xe8, 0xdd, 0xcd, 0x64, 0x71
	};
	const uint8_t test_client_pub[32] = {
		0x1e, 0xc7, 0x71, 0x75, 0xb0, 0x91, 0x8e, 0xd2,
		0x06, 0xf9, 0xae, 0x04, 0xec, 0x13, 0x6d, 0x6d,
		0x5d, 0x43, 0x15, 0xbb, 0x26, 0x30, 0x54, 0x27,
		0xf6, 0x45, 0xb4, 0x92, 0xe9, 0x35, 0x0c, 0x10
	};

	uint8_t ss1[32], ss2[32];
	calcECDH(ss1, prv, test_client_pub);
	calcECDH(ss2, test_client_prv, pub);
	/* Constant-time even though this self-test runs at boot before
	 * any networking is up — hygiene + no attacker observation. */
	if (!Utils::constantTimeEqual(ss1, ss2, 32)) {
		Utils::secureZeroize(ss1, sizeof(ss1));
		Utils::secureZeroize(ss2, sizeof(ss2));
		return false;
	}

	bool nonzero = false;
	for (int i = 0; i < 32; i++) {
		if (ss1[i] != 0) { nonzero = true; break; }
	}
	Utils::secureZeroize(ss1, sizeof(ss1));
	Utils::secureZeroize(ss2, sizeof(ss2));
	return nonzero;
}

bool LocalIdentity::readFrom(const uint8_t *src, size_t len)
{
	if (len == PRV_KEY_SIZE + PUB_KEY_SIZE) {
		memcpy(prv_key, src, PRV_KEY_SIZE);
		memcpy(pub_key, src + PRV_KEY_SIZE, PUB_KEY_SIZE);
		return true;
	}
	if (len == PRV_KEY_SIZE) {
		memcpy(prv_key, src, PRV_KEY_SIZE);
		crypto_eddsa_scalarbase(pub_key, prv_key);  /* derive pub from a */
		return true;
	}
	return false;
}

size_t LocalIdentity::writeTo(uint8_t *dest, size_t max_len) const
{
	if (max_len < PRV_KEY_SIZE) return 0;
	if (max_len < PRV_KEY_SIZE + PUB_KEY_SIZE) {
		memcpy(dest, prv_key, PRV_KEY_SIZE);
		return PRV_KEY_SIZE;
	}
	memcpy(dest, prv_key, PRV_KEY_SIZE);
	memcpy(dest + PRV_KEY_SIZE, pub_key, PUB_KEY_SIZE);
	return PRV_KEY_SIZE + PUB_KEY_SIZE;
}

bool LocalIdentity::hasConsistentKeyPair() const
{
	uint8_t derived[PUB_KEY_SIZE];
	crypto_eddsa_scalarbase(derived, prv_key);
	return memcmp(derived, pub_key, PUB_KEY_SIZE) == 0;
}

void LocalIdentity::rederivePubKey()
{
	crypto_eddsa_scalarbase(pub_key, prv_key);
}

void LocalIdentity::sign(uint8_t *sig, const uint8_t *message, int msg_len) const
{
	signExpanded(sig, prv_key, pub_key, message, (size_t)msg_len);
}

void LocalIdentity::calcSharedSecret(uint8_t *secret, const uint8_t *other_pub_key) const
{
	calcECDH(secret, prv_key, other_pub_key);
}

} /* namespace mesh */
```

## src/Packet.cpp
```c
#include <mesh/Packet.h>
#include <mesh/Utils.h>  // ZEPHCORE: SHA-256 via Utils (no Arduino SHA256 class)
#include <string.h>

// ZEPHCORE: log module backing MESH_DEBUG_PRINTLN (see MeshCore.h).
#include <zephyr/logging/log.h>
LOG_MODULE_DECLARE(zephcore_mesh, CONFIG_ZEPHCORE_MAIN_LOG_LEVEL);

namespace mesh {

Packet::Packet() {
  header = 0;
  path_len = 0;
  payload_len = 0;
}

bool Packet::isValidPathLen(uint8_t path_len) {
  uint8_t hash_count = path_len & 63;
  uint8_t hash_size = (path_len >> 6) + 1;
  if (hash_size == 4) return false;  // Reserved for future
  return hash_count*hash_size <= MAX_PATH_SIZE;
}

size_t Packet::writePath(uint8_t* dest, const uint8_t* src, size_t src_len, uint8_t path_len) {
  uint8_t hash_count = path_len & 63;
  uint8_t hash_size = (path_len >> 6) + 1;
  size_t len = hash_count*hash_size;
  if (len > MAX_PATH_SIZE) {
    MESH_DEBUG_PRINTLN("Packet::copyPath, invalid path_len=%d", (uint32_t)path_len);
    return 0;   // Error
  }
  if (len > src_len) return 0;  // ZEPHCORE: would read past the caller-supplied source bound
  memcpy(dest, src, len);
  return len;
}

uint8_t Packet::copyPath(uint8_t* dest, const uint8_t* src, size_t src_len, uint8_t path_len) {
  // ZEPHCORE: 0 means "rejected" (upstream always returns path_len). A zero-hop
  // path copies nothing, so validate it instead of copying: a directly-heard
  // 2-byte-hash advert (0x40) must keep its hash-size bits.
  if ((path_len & 0x3F) == 0) {
    return isValidPathLen(path_len) ? path_len : 0;
  }
  return writePath(dest, src, src_len, path_len) > 0 ? path_len : 0;
}

int Packet::getRawLength() const {
  return 2 + getPathByteLen() + payload_len + (hasTransportCodes() ? 4 : 0);
}

void Packet::calculatePacketHash(uint8_t* hash) const {
  // ZEPHCORE: one-shot Utils::sha256 over (type [, path_len], payload), same digest
  // as upstream's incremental SHA256.
  uint8_t t = getPayloadType();
  if (t == PAYLOAD_TYPE_TRACE) {   // CAVEAT: TRACE packets can revisit same node on return path
    uint8_t buf[2 + MAX_PACKET_PAYLOAD];
    buf[0] = t;
    memcpy(buf + 1, &path_len, sizeof(path_len));
    memcpy(buf + 2, payload, payload_len);
    Utils::sha256(hash, MAX_HASH_SIZE, buf, 2 + payload_len);
  } else {
    uint8_t buf[1 + MAX_PACKET_PAYLOAD];
    buf[0] = t;
    memcpy(buf + 1, payload, payload_len);
    Utils::sha256(hash, MAX_HASH_SIZE, buf, 1 + payload_len);
  }
}

uint8_t Packet::writeTo(uint8_t dest[]) const {
  uint8_t i = 0;
  dest[i++] = header;
  if (hasTransportCodes()) {
    memcpy(&dest[i], &transport_codes[0], 2); i += 2;
    memcpy(&dest[i], &transport_codes[1], 2); i += 2;
  }
  dest[i++] = path_len;
  i += writePath(&dest[i], path, path_len);
  memcpy(&dest[i], payload, payload_len); i += payload_len;
  return i;
}

bool Packet::readFrom(const uint8_t src[], uint8_t len) {
  uint8_t i = 0;
  if (len < 2) return false;  // ZEPHCORE: bounds
  header = src[i++];
  if (hasTransportCodes()) {
    if (len < 6) return false;  // ZEPHCORE
    memcpy(&transport_codes[0], &src[i], 2); i += 2;
    memcpy(&transport_codes[1], &src[i], 2); i += 2;
  } else {
    transport_codes[0] = transport_codes[1] = 0;
  }
  path_len = src[i++];
  if (!isValidPathLen(path_len)) return false;   // bad encoding

  uint8_t bl = getPathByteLen();
  if ((uint16_t)i + bl > len) return false;  // ZEPHCORE
  memcpy(path, &src[i], bl); i += bl;

  if (i >= len) return false;   // bad encoding
  payload_len = len - i;
  if (payload_len > sizeof(payload)) return false;  // bad encoding
  memcpy(payload, &src[i], payload_len); //i += payload_len;
  return true;   // success
}

}
```

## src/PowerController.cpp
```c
/*
 * SPDX-License-Identifier: Apache-2.0
 * Adaptive Power Control — echo-based TX power reduction
 */

#include <mesh/PowerController.h>
#include <mesh/Packet.h>
#include <string.h>

#include <zephyr/logging/log.h>
LOG_MODULE_REGISTER(zephcore_apc, CONFIG_ZEPHCORE_MAIN_LOG_LEVEL);

/* SNR thresholds per SF (x4 fixed point, matching radio_common.h) */
static constexpr int8_t snr_threshold_x4[] = {
	-30, /* SF7:  -7.5 dB */
	-40, /* SF8: -10.0 dB */
	-50, /* SF9: -12.5 dB */
	-60, /* SF10: -15.0 dB */
	-70, /* SF11: -17.5 dB */
	-80, /* SF12: -20.0 dB */
};

namespace mesh {

PowerController::PowerController()
	: _next_idx(0), _margin_ema_x256(0), _finalized_count(0),
	  _last_echo_ms(0), _power_reduction_db(0), _enabled(true),
	  _sf(8), _last_source_count(0), _target_margin_x4(DEFAULT_TARGET_MARGIN_X4)
{
	memset(_ring, 0, sizeof(_ring));
}

void PowerController::setEnabled(bool en)
{
	if (_enabled == en) return;
	_enabled = en;
	if (!_enabled) {
		/* Drop APC runtime state while disabled so no tracking work runs. */
		memset(_ring, 0, sizeof(_ring));
		_next_idx = 0;
		_margin_ema_x256 = 0;
		_finalized_count = 0;
		_last_echo_ms = 0;
		_last_source_count = 0;
		_power_reduction_db = 0;
	}
}

int8_t PowerController::sfThresholdX4(uint8_t sf)
{
	int idx = (int)sf - 7;
	if (idx < 0) idx = 0;
	if (idx > 5) idx = 5;
	return snr_threshold_x4[idx];
}

int PowerController::findEntry(uint32_t hash32) const
{
	for (int i = 0; i < RING_SIZE; i++) {
		if (_ring[i].active && _ring[i].hash32 == hash32) {
			return i;
		}
	}
	return -1;
}

void PowerController::trackTransmit(uint32_t hash32, uint32_t now_ms)
{
	if (!_enabled) return;

	/* If ring slot is occupied, finalize it first */
	if (_ring[_next_idx].active) {
		finalizeEntry(_next_idx);
	}

	EchoEntry &e = _ring[_next_idx];
	e.hash32 = hash32;
	e.timestamp_ms = now_ms;
	e.source_count = 0;
	e.sf_at_track = _sf;
	memset(e.sources, 0, sizeof(e.sources));
	e.active = true;

	_next_idx = (_next_idx + 1) % RING_SIZE;
}

bool PowerController::recordEcho(uint32_t hash32, int8_t snr_x4,
				 uint8_t first_hop_hash, uint32_t now_ms)
{
	if (!_enabled) return false;

	int idx = findEntry(hash32);
	if (idx < 0) return false;

	EchoEntry &e = _ring[idx];

	/* Check if entry has expired */
	if (now_ms - e.timestamp_ms > ECHO_WINDOW_MS) {
		finalizeEntry(idx);
		return false;
	}

	/* Update existing source or add new one */
	for (int i = 0; i < e.source_count; i++) {
		if (e.sources[i].hash == first_hop_hash) {
			if (snr_x4 > e.sources[i].snr_x4) {
				e.sources[i].snr_x4 = snr_x4;
			}
			_last_echo_ms = now_ms;
			return true;
		}
	}

	if (e.source_count < MAX_SOURCES) {
		e.sources[e.source_count].hash = first_hop_hash;
		e.sources[e.source_count].snr_x4 = snr_x4;
		e.source_count++;
	}

	_last_echo_ms = now_ms;
	return true;
}

int8_t PowerController::computeRobustSNR(const EchoEntry &entry) const
{
	if (entry.source_count == 0) {
		return sfThresholdX4(entry.sf_at_track); /* no echo = margin 0 */
	}

	if (entry.source_count == 1) {
		return entry.sources[0].snr_x4;
	}

	/* 2-3 sources: sort descending, then cluster + rogue filter */
	int8_t sorted[MAX_SOURCES];
	int n = entry.source_count;
	for (int i = 0; i < n; i++) {
		sorted[i] = entry.sources[i].snr_x4;
	}
	/* Simple insertion sort (max 3 elements) */
	for (int i = 1; i < n; i++) {
		int8_t key = sorted[i];
		int j = i - 1;
		while (j >= 0 && sorted[j] < key) {
			sorted[j + 1] = sorted[j];
			j--;
		}
		sorted[j + 1] = key;
	}

	/* Count how many are within CLUSTER_WIDTH of the best */
	int cluster_count = 1;
	for (int i = 1; i < n; i++) {
		if (sorted[0] - sorted[i] <= CLUSTER_WIDTH_X4) {
			cluster_count++;
		}
	}

	if (cluster_count >= 2) {
		/* 2+ in cluster: median of the cluster values */
		/* For 2 values: average. For 3 values: middle one. */
		if (cluster_count == 2) {
			return (int8_t)(((int)sorted[0] + (int)sorted[1]) / 2);
		}
		/* cluster_count == 3 (all 3 within 6 dB) */
		return sorted[1]; /* median */
	}

	/* Only 1 in top cluster → rogue. Drop it, use next. */
	if (n >= 3 && sorted[1] - sorted[2] <= CLUSTER_WIDTH_X4) {
		/* sources[1] and [2] cluster together — median them */
		return (int8_t)(((int)sorted[1] + (int)sorted[2]) / 2);
	}
	/* Fall back to second-best */
	return sorted[1];
}

void PowerController::finalizeEntry(int idx)
{
	if (!_ring[idx].active) return;

	EchoEntry &e = _ring[idx];
	_last_source_count = e.source_count;

	int8_t robust_snr = computeRobustSNR(e);
	int32_t margin_x4 = (int32_t)robust_snr - (int32_t)sfThresholdX4(e.sf_at_track);
	/* margin_x4 is in x4 units. Convert to x256 for EMA. */
	int32_t sample_x256 = margin_x4 << 6; /* x4 * 64 = x256 */

	int32_t diff = sample_x256 - _margin_ema_x256;

	if (_finalized_count < WARMUP_COUNT) {
		/* During warmup, seed the EMA faster */
		if (_finalized_count == 0) {
			_margin_ema_x256 = sample_x256;
		} else {
			_margin_ema_x256 += diff >> 1;
		}
	} else {
		/* Normal EMA update: ema += (sample - ema) >> shift */
		_margin_ema_x256 += diff >> EMA_SHIFT;
	}

	_finalized_count++;
	e.active = false;

	LOG_DBG("APC finalize: sources=%d robust_snr=%.1f margin=%.1f ema=%.1f",
		(int)_last_source_count,
		(double)(robust_snr / 4.0f),
		(double)(margin_x4 / 4.0f),
		(double)getMarginEstimate());
}

void PowerController::tick(uint32_t now_ms)
{
	if (!_enabled) return;

	/* Finalize expired entries */
	for (int i = 0; i < RING_SIZE; i++) {
		if (_ring[i].active && now_ms - _ring[i].timestamp_ms > ECHO_WINDOW_MS) {
			finalizeEntry(i);
		}
	}

	if (!isWarmedUp()) return;

	int32_t margin_x256 = _margin_ema_x256;
	int32_t target_x256 = _target_margin_x4 << 6;
	int32_t hyst_x256 = HYSTERESIS_X4 << 6;

	int8_t old_reduction = _power_reduction_db;

	/* Staleness takes priority: ramp back to full power if no echoes.
	 * When stale, never increase reduction — old EMA data is unreliable. */
	if (isStale(now_ms)) {
		if (_power_reduction_db > 0) {
			_power_reduction_db -= STEP_DOWN_DB;
			if (_power_reduction_db < 0) {
				_power_reduction_db = 0;
			}
		}
	} else if (margin_x256 > target_x256 + hyst_x256) {
		/* Margin very good — step down */
		if (_power_reduction_db < MAX_REDUCTION_DB) {
			_power_reduction_db += STEP_DOWN_DB;
			if (_power_reduction_db > MAX_REDUCTION_DB) {
				_power_reduction_db = MAX_REDUCTION_DB;
			}
		}
	} else if (margin_x256 < target_x256 - hyst_x256) {
		/* Margin too low — step up (reduce the reduction) */
		if (_power_reduction_db > 0) {
			_power_reduction_db -= STEP_UP_DB;
			if (_power_reduction_db < 0) {
				_power_reduction_db = 0;
			}
		}
	}

	if (_power_reduction_db != old_reduction) {
		LOG_INF("APC: reduction %d -> %d dBm (margin=%.1f)",
			(int)old_reduction, (int)_power_reduction_db,
			(double)getMarginEstimate());
	}
}

float PowerController::getMarginEstimate() const
{
	return (float)_margin_ema_x256 / 256.0f;
}

bool PowerController::isStale(uint32_t now_ms) const
{
	if (_last_echo_ms == 0) return false;
	return now_ms - _last_echo_ms > STALE_MS;
}

} /* namespace mesh */
```

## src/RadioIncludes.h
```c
/*
 * SPDX-License-Identifier: MIT
 * ZephCore - Common radio includes for LoRa mesh roles
 *
 * Shared by companion, repeater, and any future role that uses the
 * LoRa radio.  Selects LR1110 or SX126x based on Kconfig/devicetree.
 */

#ifndef ZEPHCORE_RADIO_INCLUDES_H
#define ZEPHCORE_RADIO_INCLUDES_H

#if IS_ENABLED(CONFIG_ZEPHCORE_RADIO_LR1110) || DT_NODE_HAS_STATUS(DT_ALIAS(lora0), okay)

#include <zephyr/drivers/lora.h>
#include <helpers/LoRaConfig.h>
#include <adapters/board/ZephyrBoard.h>
#include <adapters/clock/ZephyrMillisecondClock.h>
#include <adapters/rng/ZephyrRNG.h>
#include <mesh/SimpleMeshTables.h>
#include <mesh/StaticPoolPacketManager.h>

#include <adapters/radio/LoRaRadio.h>

#define ZEPHCORE_LORA 1

#endif /* CONFIG_ZEPHCORE_RADIO_LR1110 || lora0 */

#endif /* ZEPHCORE_RADIO_INCLUDES_H */
```

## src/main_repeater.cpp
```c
/*
 * SPDX-License-Identifier: MIT
 * ZephCore - Repeater
 *
 * The repeater role's entry point: its mesh object, and the ServerRole that
 * hands it to the shared server code (server_main_common.cpp).
 */

#include "server_main_common.h"
#include <app/RepeaterMesh.h>

#ifdef ZEPHCORE_LORA
/* RepeaterMesh requires: board, radio, ms_clock, rng, rtc, tables */
static RepeaterMesh repeater_mesh(zephyr_board, lora_radio, ms_clock, zephyr_rng, rtc_clock, mesh_tables);
#endif

static const ServerRole repeater_role = {
	.name = "Repeater",
	.name_prefix = "Repeater",
#ifdef ZEPHCORE_LORA
	.mesh = &repeater_mesh,
	.callbacks = &repeater_mesh,
	.prefs = repeater_mesh.getNodePrefs(),
	.begin = [](RepeaterDataStore *store) { repeater_mesh.begin(store); },
	.loop = [] { repeater_mesh.loop(); },
	.handle_command = [](char *command, char *reply) { repeater_mesh.handleCommand(0, command, reply); },
	.note_gps_time_sync = [] { repeater_mesh.noteGPSTimeSync(); },
#endif
};

int main(void)
{
	return server_main(repeater_role);
}
```
